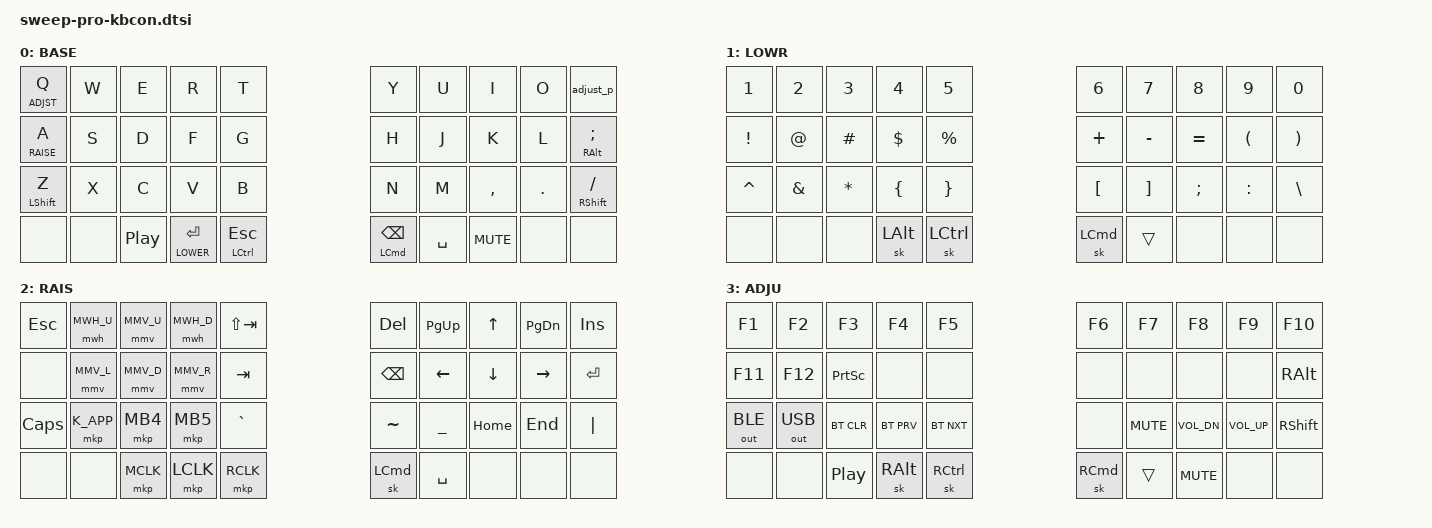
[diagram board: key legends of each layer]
#include <behaviors.dtsi>
#include <dt-bindings/zmk/keys.h>
#include <dt-bindings/zmk/bt.h>
#include <dt-bindings/zmk/outputs.h>
#include <dt-bindings/zmk/mouse.h>

#define DEFLT 0
#define LOWER 1
#define RAISE 2
#define ADJST 3

// mouse move settings
#define MMV_U MOVE_VERT(-650)
#define MMV_D MOVE_VERT(650)
#define MMV_L MOVE_HOR(-650)
#define MMV_R MOVE_HOR(650)

&mmv {
  time-to-max-speed-ms = <500>;
  acceleration-exponent=<1>;
};

// mouse wheel settings
#define MWH_U SCROLL_VERT(15)
#define MWH_D SCROLL_VERT(-15)
#define MWH_L SCROLL_HOR(-15)
#define MWH_R SCROLL_HOR(15)

&mwh {    
  time-to-max-speed-ms = <2000>;
  acceleration-exponent=<0>;
};

&mt {
  flavor = "tap-preferred";
  tapping-term-ms = <200>;
  quick-tap-ms = <200>;
};

&lt {
  flavor = "tap-preferred";
  tapping-term-ms = <200>;
  quick-tap-ms = <200>;
};

/ {

  behaviors {
    mp: mod_preferred {
      compatible = "zmk,behavior-hold-tap";
      label = "MOD_PREFERRED";
      flavor = "hold-preferred";
      tapping-term-ms = <200>;
      quick-tap-ms = <200>;
      #binding-cells = <2>;
      bindings = <&kp>, <&kp>;
    };

    lp: layer_preferred {
      compatible = "zmk,behavior-hold-tap";
      label = "LAYER_PREFERRED";
      flavor = "hold-preferred";
      tapping-term-ms = <200>;
      quick-tap-ms = <0>;
      #binding-cells = <2>;
      bindings = <&mo>, <&kp>;
    };

    adjust_p: mod_morph_adjust_p {
      compatible = "zmk,behavior-mod-morph";
      label = "MOD_MORPH_ADJUST_P";
      #binding-cells = <0>;
      bindings = <&lt ADJST P>, <&kp P>;
      mods = <(MOD_LCTL|MOD_RCTL|MOD_LALT|MOD_RALT)>;
    };
  };

  keymap {
    compatible = "zmk,keymap";
    default_layer {
      label = "BASE";
      bindings = <
                 &lt ADJST Q &kp W &kp E &kp R &kp T               &kp Y &kp U &kp I &kp O &adjust_p
                 &lt RAISE A &kp S &kp D &kp F &kp G               &kp H &kp J &kp K &kp L &mp RALT SEMI
                 &mt LSHFT Z &kp X &kp C &kp V &kp B               &kp N &kp M &kp COMMA &kp DOT &mp RSHFT SLASH
                 &none &none &kp C_PP &lp LOWER RET &mp LCTRL ESC  &mp LCMD BSPC &kp SPACE &kp C_MUTE &none &none
                 >;
      sensor-bindings = <&inc_dec_kp RIGHT LEFT &inc_dec_kp UP DOWN>;
    };

    lower_layer {
      label = "LOWR";
      bindings = <
                 &kp N1    &kp N2    &kp N3    &kp N4    &kp N5    &kp N6    &kp N7    &kp N8    &kp N9    &kp N0
                 &kp EXCL  &kp AT    &kp HASH  &kp DLLR  &kp PRCNT &kp PLUS  &kp MINUS &kp EQUAL &kp LPAR  &kp RPAR
                 &kp CARET &kp AMPS  &kp ASTRK &kp LBRC  &kp RBRC  &kp LBKT  &kp RBKT  &kp SEMI  &kp COLON &kp BSLH
                 &none     &none     &none     &sk LALT  &sk LCTRL &sk LCMD  &trans    &none     &none     &none
                 >;
      sensor-bindings = <&inc_dec_kp TAB LS(TAB) &inc_dec_kp PG_UP PG_DN>;
    };

    raise_layer {
      label = "RAIS";
      bindings = <
                 &kp ESC   &mwh MWH_U &mmv MMV_U &mwh MWH_D &kp LS(TAB) &kp DEL &kp PG_UP &kp UP    &kp PG_DN &kp INS
                 &none     &mmv MMV_L &mmv MMV_D &mmv MMV_R &kp TAB   &kp BSPC  &kp LEFT  &kp DOWN  &kp RIGHT &kp ENTER
                 &kp CAPS  &mkp K_APP &mkp MB4   &mkp MB5   &kp GRAVE &kp TILDE &kp UNDER &kp HOME  &kp END   &kp PIPE
                 &none     &none      &mkp MCLK  &mkp LCLK  &mkp RCLK &sk LCMD  &kp SPACE &none     &none     &none
                 >;
      sensor-bindings = <&inc_dec_kp TAB LS(TAB) &inc_dec_kp PG_UP PG_DN>;
    };

    adjust_layer {
      label = "ADJU";
      bindings = <
                 &kp F1    &kp F2     &kp F3     &kp F4     &kp F5    &kp F6    &kp F7    &kp F8    &kp F9    &kp F10
                 &kp F11   &kp F12    &kp PSCRN  &none      &none     &none     &none     &none     &none     &kp RALT
                 &out OUT_BLE &out OUT_USB &bt BT_CLR &bt BT_PRV &bt BT_NXT &none &kp C_MUTE &kp C_VOL_DN &kp C_VOL_UP &kp RSHFT
                 &none     &none      &kp C_PP   &sk RALT   &sk RCTRL &sk RCMD  &trans    &kp C_MUTE &none    &none
                 >;
      sensor-bindings = <&inc_dec_kp C_NEXT C_PREV &inc_dec_kp C_VOL_DN C_VOL_UP>;
    };
  };
};
